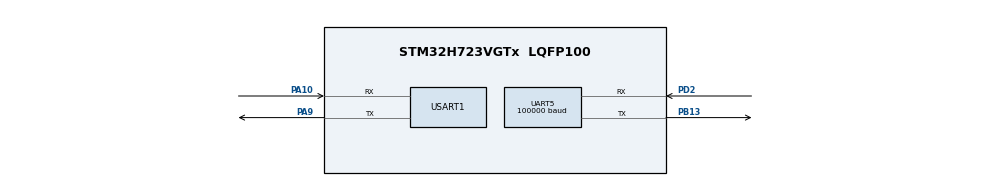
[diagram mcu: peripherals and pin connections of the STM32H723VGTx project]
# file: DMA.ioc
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CORTEX_M7.AccessPermission_S-Cortex_Memory_Protection_Unit_Region1_Settings_S=MPU_REGION_PRIV_RO
CORTEX_M7.BaseAddress_S-Cortex_Memory_Protection_Unit_Region1_Settings_S=0x08000000
CORTEX_M7.Enable_S-Cortex_Memory_Protection_Unit_Region1_Settings_S=MPU_REGION_ENABLE
CORTEX_M7.IsCacheable_S-Cortex_Memory_Protection_Unit_Region1_Settings_S=MPU_ACCESS_CACHEABLE
CORTEX_M7.Size_S-Cortex_Memory_Protection_Unit_Region1_Settings_S=MPU_REGION_SIZE_1MB
CORTEX_M7.TypeExtField_S-Cortex_Memory_Protection_Unit_Region1_Settings_S=MPU_TEX_LEVEL1
CORTEX_M7.default_mode_Activation=1
Dma.Request0=UART5_RX
Dma.Request1=USART1_RX
Dma.UART5_RX.0.Direction=DMA_PERIPH_TO_MEMORY
Dma.UART5_RX.0.EventEnable=DISABLE
Dma.UART5_RX.0.FIFOMode=DMA_FIFOMODE_DISABLE
Dma.UART5_RX.0.Instance=DMA1_Stream0
Dma.UART5_RX.0.MemDataAlignment=DMA_MDATAALIGN_BYTE
Dma.UART5_RX.0.MemInc=DMA_MINC_ENABLE
Dma.UART5_RX.0.Mode=DMA_CIRCULAR
Dma.UART5_RX.0.PeriphDataAlignment=DMA_PDATAALIGN_BYTE
Dma.UART5_RX.0.PeriphInc=DMA_PINC_DISABLE
Dma.UART5_RX.0.Polarity=HAL_DMAMUX_REQ_GEN_RISING
Dma.UART5_RX.0.Priority=DMA_PRIORITY_LOW
Dma.UART5_RX.0.RequestNumber=1
Dma.UART5_RX.0.SignalID=NONE
Dma.UART5_RX.0.SyncEnable=DISABLE
Dma.UART5_RX.0.SyncPolarity=HAL_DMAMUX_SYNC_NO_EVENT
Dma.UART5_RX.0.SyncRequestNumber=1
Dma.UART5_RX.0.SyncSignalID=NONE
Dma.USART1_RX.1.Direction=DMA_PERIPH_TO_MEMORY
Dma.USART1_RX.1.EventEnable=DISABLE
Dma.USART1_RX.1.FIFOMode=DMA_FIFOMODE_DISABLE
Dma.USART1_RX.1.Instance=DMA1_Stream1
Dma.USART1_RX.1.MemDataAlignment=DMA_MDATAALIGN_BYTE
Dma.USART1_RX.1.MemInc=DMA_MINC_ENABLE
Dma.USART1_RX.1.Mode=DMA_CIRCULAR
Dma.USART1_RX.1.PeriphDataAlignment=DMA_PDATAALIGN_BYTE
Dma.USART1_RX.1.PeriphInc=DMA_PINC_DISABLE
Dma.USART1_RX.1.Polarity=HAL_DMAMUX_REQ_GEN_RISING
Dma.USART1_RX.1.Priority=DMA_PRIORITY_LOW
Dma.USART1_RX.1.RequestNumber=1
Dma.USART1_RX.1.SignalID=NONE
Dma.USART1_RX.1.SyncEnable=DISABLE
Dma.USART1_RX.1.SyncPolarity=HAL_DMAMUX_SYNC_NO_EVENT
Dma.USART1_RX.1.SyncRequestNumber=1
Dma.USART1_RX.1.SyncSignalID=NONE
Mcu.Family=STM32H7
Mcu.Name=STM32H723VGTx
Mcu.Package=LQFP100
NVIC.DMA1_Stream0_IRQn=true\:0\:0\:false\:false\:true\:false\:true\:true
NVIC.DMA1_Stream1_IRQn=true\:0\:0\:false\:false\:true\:false\:true\:true
NVIC.PriorityGroup=NVIC_PRIORITYGROUP_4
NVIC.UART5_IRQn=true\:0\:0\:false\:false\:true\:true\:true\:true
NVIC.USART1_IRQn=true\:0\:0\:false\:false\:true\:true\:true\:true
PA10.Mode=Asynchronous
PA10.Signal=USART1_RX
PA9.Mode=Asynchronous
PA9.Signal=USART1_TX
PB13.Mode=Asynchronous
PB13.Signal=UART5_TX
PD2.Mode=Asynchronous
PD2.Signal=UART5_RX
ProjectManager.HeapSize=0x200
ProjectManager.StackSize=0x400
ProjectManager.TargetToolchain=CMake
RCC.ADCFreq_Value=129000000
RCC.APB1Freq_Value=32000000
RCC.APB2Freq_Value=32000000
RCC.APB3Freq_Value=64000000
RCC.APB4Freq_Value=64000000
RCC.CortexFreq_Value=64000000
RCC.D2PPRE1=RCC_APB1_DIV2
RCC.D2PPRE2=RCC_APB2_DIV2
RCC.HCLKFreq_Value=64000000
RCC.SYSCLKFreq_VALUE=64000000
RCC.USBFreq_Value=129000000
UART5.BaudRate=100000
UART5.Parity=PARITY_EVEN
UART5.StopBits=UART_STOPBITS_2
USART1.VirtualMode-Asynchronous=VM_ASYNC
VP_MEMORYMAP_VS_MEMORYMAP.Mode=CurAppReg
board=custom

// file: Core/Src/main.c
/* USER CODE BEGIN Header */
/**
  ******************************************************************************
  * @file           : main.c
  * @brief          : Main program body
  ******************************************************************************
  * @attention
  *
  * Copyright (c) 2025 STMicroelectronics.
  * All rights reserved.
  *
  * This software is licensed under terms that can be found in the LICENSE file
  * in the root directory of this software component.
  * If no LICENSE file comes with this software, it is provided AS-IS.
  *
  ******************************************************************************
  */
/* USER CODE END Header */
#include "main.h"
#include "dma.h"
#include "memorymap.h"
#include "usart.h"
#include "gpio.h"

/* USER CODE BEGIN PV */
__attribute__((section(".sram4"))) uint8_t uart_rx_buffer[25];

/* USER CODE END PV */

void SystemClock_Config(void);
static void MPU_Config(void);

int main(void)
{

  /* MPU Configuration--------------------------------------------------------*/
  MPU_Config();

  /* MCU Configuration--------------------------------------------------------*/

  /* Reset of all peripherals, Initializes the Flash interface and the Systick. */
  HAL_Init();

  /* Configure the system clock */
  SystemClock_Config();

  /* Initialize all configured peripherals */
  MX_GPIO_Init();
  MX_DMA_Init();
  MX_UART5_Init();
  MX_USART1_UART_Init();
  /* USER CODE BEGIN 2 */
  for (int i = 0; i <25; i++){uart_rx_buffer [i]=0;}
  HAL_UART_Receive_DMA(&huart1, uart_rx_buffer, 25);
  HAL_Delay(9000);
  int a = 0;
  /* USER CODE END 2 */

  /* Infinite loop */
  while (1)
  {

  }
}

void SystemClock_Config(void)
{
  RCC_OscInitTypeDef RCC_OscInitStruct = {0};
  RCC_ClkInitTypeDef RCC_ClkInitStruct = {0};

  /** Supply configuration update enable
  */
  HAL_PWREx_ConfigSupply(PWR_LDO_SUPPLY);

  /** Configure the main internal regulator output voltage
  */
  __HAL_PWR_VOLTAGESCALING_CONFIG(PWR_REGULATOR_VOLTAGE_SCALE3);

  while(!__HAL_PWR_GET_FLAG(PWR_FLAG_VOSRDY)) {}

  /** Initializes the RCC Oscillators according to the specified parameters
  * in the RCC_OscInitTypeDef structure.
  */
  RCC_OscInitStruct.OscillatorType = RCC_OSCILLATORTYPE_HSI;
  RCC_OscInitStruct.HSIState = RCC_HSI_DIV1;
  RCC_OscInitStruct.HSICalibrationValue = 64;
  RCC_OscInitStruct.PLL.PLLState = RCC_PLL_NONE;
  if (HAL_RCC_OscConfig(&RCC_OscInitStruct) != HAL_OK)
  {
    Error_Handler();
  }

  /** Initializes the CPU, AHB and APB buses clocks
  */
  RCC_ClkInitStruct.ClockType = RCC_CLOCKTYPE_HCLK|RCC_CLOCKTYPE_SYSCLK
                              |RCC_CLOCKTYPE_PCLK1|RCC_CLOCKTYPE_PCLK2
                              |RCC_CLOCKTYPE_D3PCLK1|RCC_CLOCKTYPE_D1PCLK1;
  RCC_ClkInitStruct.SYSCLKSource = RCC_SYSCLKSOURCE_HSI;
  RCC_ClkInitStruct.SYSCLKDivider = RCC_SYSCLK_DIV1;
  RCC_ClkInitStruct.AHBCLKDivider = RCC_HCLK_DIV1;
  RCC_ClkInitStruct.APB3CLKDivider = RCC_APB3_DIV1;
  RCC_ClkInitStruct.APB1CLKDivider = RCC_APB1_DIV2;
  RCC_ClkInitStruct.APB2CLKDivider = RCC_APB2_DIV2;
  RCC_ClkInitStruct.APB4CLKDivider = RCC_APB4_DIV1;

  if (HAL_RCC_ClockConfig(&RCC_ClkInitStruct, FLASH_LATENCY_1) != HAL_OK)
  {
    Error_Handler();
  }
}

 /* MPU Configuration */

void MPU_Config(void)
{
  MPU_Region_InitTypeDef MPU_InitStruct = {0};

  /* Disables the MPU */
  HAL_MPU_Disable();

  /** Initializes and configures the Region and the memory to be protected
  */
  MPU_InitStruct.Enable = MPU_REGION_ENABLE;
  MPU_InitStruct.Number = MPU_REGION_NUMBER0;
  MPU_InitStruct.BaseAddress = 0x0;
  MPU_InitStruct.Size = MPU_REGION_SIZE_4GB;
  MPU_InitStruct.SubRegionDisable = 0x87;
  MPU_InitStruct.TypeExtField = MPU_TEX_LEVEL0;
  MPU_InitStruct.AccessPermission = MPU_REGION_NO_ACCESS;
  MPU_InitStruct.DisableExec = MPU_INSTRUCTION_ACCESS_DISABLE;
  MPU_InitStruct.IsShareable = MPU_ACCESS_SHAREABLE;
  MPU_InitStruct.IsCacheable = MPU_ACCESS_NOT_CACHEABLE;
  MPU_InitStruct.IsBufferable = MPU_ACCESS_NOT_BUFFERABLE;

  HAL_MPU_ConfigRegion(&MPU_InitStruct);

  /** Initializes and configures the Region and the memory to be protected
  */
  MPU_InitStruct.Number = MPU_REGION_NUMBER1;
  MPU_InitStruct.BaseAddress = 0x08000000;
  MPU_InitStruct.Size = MPU_REGION_SIZE_1MB;
  MPU_InitStruct.SubRegionDisable = 0x0;
  MPU_InitStruct.TypeExtField = MPU_TEX_LEVEL1;
  MPU_InitStruct.AccessPermission = MPU_REGION_PRIV_RO;
  MPU_InitStruct.DisableExec = MPU_INSTRUCTION_ACCESS_ENABLE;
  MPU_InitStruct.IsShareable = MPU_ACCESS_NOT_SHAREABLE;
  MPU_InitStruct.IsCacheable = MPU_ACCESS_CACHEABLE;

  HAL_MPU_ConfigRegion(&MPU_InitStruct);
  /* Enables the MPU */
  HAL_MPU_Enable(MPU_PRIVILEGED_DEFAULT);

}

void Error_Handler(void)
{
  __disable_irq();
  while (1)
  {
  }
}
